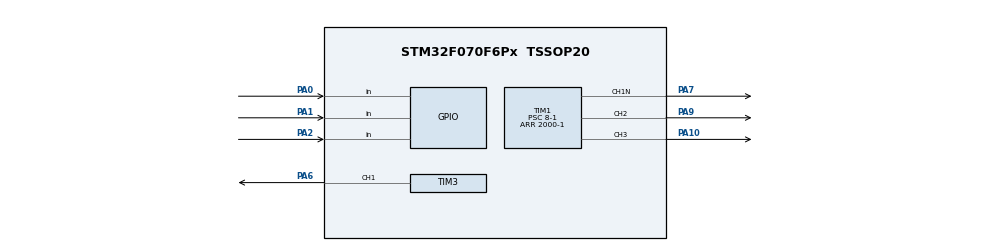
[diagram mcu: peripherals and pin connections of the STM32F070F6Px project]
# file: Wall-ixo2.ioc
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Mcu.Family=STM32F0
Mcu.Name=STM32F070F6Px
Mcu.Package=TSSOP20
PA0.GPIO_PuPd=GPIO_PULLDOWN
PA0.Signal=GPIO_Input
PA1.GPIO_PuPd=GPIO_PULLDOWN
PA1.Signal=GPIO_Input
PA10.Signal=S_TIM1_CH3
PA13.Mode=Serial_Wire
PA13.Signal=SYS_SWDIO
PA14.Mode=Serial_Wire
PA14.Signal=SYS_SWCLK
PA2.GPIO_PuPd=GPIO_PULLDOWN
PA2.Signal=GPIO_Input
PA6.Signal=S_TIM3_CH1
PA7.Mode=PWM Generation1 CH1N
PA7.Signal=TIM1_CH1N
PA9.Signal=S_TIM1_CH2
ProjectManager.HeapSize=0x200
ProjectManager.StackSize=0x400
ProjectManager.TargetToolchain=STM32CubeIDE
SH.S_TIM1_CH2.0=TIM1_CH2,PWM Generation2 CH2
SH.S_TIM1_CH3.0=TIM1_CH3,PWM Generation3 CH3
SH.S_TIM3_CH1.0=TIM3_CH1,PWM Generation1 CH1
TIM1.Channel-PWM\ Generation1\ CH1N=TIM_CHANNEL_1
TIM1.Channel-PWM\ Generation2\ CH2=TIM_CHANNEL_2
TIM1.Channel-PWM\ Generation3\ CH3=TIM_CHANNEL_3
TIM1.Period=2000-1
TIM1.Prescaler=8-1
TIM3.Channel-PWM\ Generation1\ CH1=TIM_CHANNEL_1
TIM3.Period=2000-1
TIM3.Prescaler=8-1
VP_TIM1_VS_ClockSourceINT.Mode=Internal
board=custom

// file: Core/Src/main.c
/* USER CODE BEGIN Header */
/**
  ******************************************************************************
  * @file           : main.c
  * @brief          : Main program body
  ******************************************************************************
  * @attention
  *
  * Copyright (c) 2022 STMicroelectronics.
  * All rights reserved.
  *
  * This software is licensed under terms that can be found in the LICENSE file
  * in the root directory of this software component.
  * If no LICENSE file comes with this software, it is provided AS-IS.
  *
  ******************************************************************************
  */
/* USER CODE END Header */
#include "main.h"

TIM_HandleTypeDef htim1;
TIM_HandleTypeDef htim3;

void SystemClock_Config(void);
static void MX_GPIO_Init(void);
static void MX_TIM1_Init(void);
static void MX_TIM3_Init(void);

int main(void)
{

  /* MCU Configuration--------------------------------------------------------*/

  /* Reset of all peripherals, Initializes the Flash interface and the Systick. */
  HAL_Init();

  /* Configure the system clock */
  SystemClock_Config();

  /* Initialize all configured peripherals */
  MX_GPIO_Init();
  MX_TIM1_Init();
  MX_TIM3_Init();
  /* USER CODE BEGIN 2 */
  	  HAL_TIM_PWM_Start(&htim1, TIM_CHANNEL_1); //PA7
      HAL_TIM_PWM_Start(&htim1, TIM_CHANNEL_2);//PA9
      HAL_TIM_PWM_Start(&htim1, TIM_CHANNEL_3);//PA10
      HAL_TIM_PWM_Start(&htim3, TIM_CHANNEL_1);//PA6
  /* USER CODE END 2 */

  /* Infinite loop */
  while (1)
  {
	  anda();
	  sensorMeio();
	  sensorDireita();
	  sensorEsquerdo();
  }
}
void sensorMeio(){
	if(HAL_GPIO_ReadPin(GPIOA, GPIO_PIN_1)){
			  para();
		      gira90();
	}
}
void sensorEsquerdo(){
	if(HAL_GPIO_ReadPin(GPIOA, GPIO_PIN_0)){
			  para();
		      gira90();
		      para();
		      andaPouco(1000);
		      para();
		      gira90Nega();
		      anda();
	}
}
void sensorDireita(){
	if(HAL_GPIO_ReadPin(GPIOA, GPIO_PIN_2)){
		para();
				      gira90Nega();
				      para();
				      andaPouco(1000);
				      para();
				      gira90();
				      anda();
	}
}
void anda(void){
	//velocidade do motor(NÃO DEFINIDA)
		int vm = 1500;
		//motor 1
		TIM1->CCR3=vm;
		TIM1->CCR2=0;
		//motor2
		TIM1->CCR1 = vm;
		TIM3->CCR1 = 0;
		HAL_Delay(10);
}
void andaPouco(int time){
	//velocidade do motor(NÃO DEFINIDA)
		int vm = 1500;
		//motor 1
		TIM1->CCR3=vm;
		TIM1->CCR2=0;
		//motor2
		TIM1->CCR1 = vm;
		TIM3->CCR1 = 0;
		HAL_Delay(time);
		para();
}
/**
  * @brief  para
  * @retval int
  */
void para(void){
		//motor 1
		TIM1->CCR3=0;
		TIM1->CCR2=0;
		//motor2
		TIM1->CCR1 = 0;
		TIM3->CCR1 = 0;
}

void gira90(void){
	//velocidade de curva do motor(NÃO DEFINIDA)
		int vcurva = 1500;
	//tempo de curva do motor(NÃO DEFINIDO)
		int tvirada = 1200;
	//motor 1 motor esquerda
		TIM1->CCR3 = 0;
		TIM1->CCR2 = vcurva;
	//motor2 motor da direita
		TIM1->CCR1 = vcurva;
		TIM3->CCR1 = 0;
		HAL_Delay(tvirada);
		para();
	//tempo necessario para a curva
	//verificando se passagem está livre
		if(HAL_GPIO_ReadPin(GPIOA, GPIO_PIN_1) == 1){
			gira180();
		}
}
void gira90Nega(void){
	//velocidade de curva do motor(NÃO DEFINIDA)
			int vcurva = 1500;
		//tempo de curva do motor(NÃO DEFINIDO)
			int tvirada = 1200;
		//motor 1 motor esquerda
			TIM1->CCR3 = vcurva;
			TIM1->CCR2 = 0;
		//motor2 motor da direita
			TIM1->CCR1 = 0;
			TIM3->CCR1 = vcurva;
			HAL_Delay(tvirada);
			para();	//verificando se passagem está livre
		if(HAL_GPIO_ReadPin(GPIOA, GPIO_PIN_1) == 1){
			gira180();
		}
}
/**
  * @brief  Função para virar 90 graus,
  * tomando como padrao o lado esquerdo
  * @retval void
  */
void gira180(void){
	//velocidade de curva do motor(NÃO DEFINIDA)
		int vcurva = 1500;
	//tempo de curva do motor(NÃO DEFINIDO)
		int tvirada = 2000;
	//motor 1
		TIM1->CCR3 = vcurva;
		TIM1->CCR2 = 0;
	//motor2
		TIM1->CCR1 = 0;
		TIM3->CCR1 = vcurva;
	//tempo necessario para a curva
		HAL_Delay(2*tvirada);
		//parando motor
		para();
	//verificando se passagem está livre
		if(HAL_GPIO_ReadPin(GPIOA, GPIO_PIN_1) == 1){
			desliga();
		}
}
/**
  * @brief  desligando
  * @retval int
  */
void desliga(){
	//motor 1
		TIM1->CCR3 = 0;
		TIM1->CCR2 = 0;
	//motor2
		TIM1->CCR1 = 0;
		TIM3->CCR1 = 0;
	//desligar vassourinhas e o aspirador;
		//
		//
		//
}
void SystemClock_Config(void)
{
  RCC_OscInitTypeDef RCC_OscInitStruct = {0};
  RCC_ClkInitTypeDef RCC_ClkInitStruct = {0};

  /** Initializes the RCC Oscillators according to the specified parameters
  * in the RCC_OscInitTypeDef structure.
  */
  RCC_OscInitStruct.OscillatorType = RCC_OSCILLATORTYPE_HSI;
  RCC_OscInitStruct.HSIState = RCC_HSI_ON;
  RCC_OscInitStruct.HSICalibrationValue = RCC_HSICALIBRATION_DEFAULT;
  RCC_OscInitStruct.PLL.PLLState = RCC_PLL_NONE;
  if (HAL_RCC_OscConfig(&RCC_OscInitStruct) != HAL_OK)
  {
    Error_Handler();
  }

  /** Initializes the CPU, AHB and APB buses clocks
  */
  RCC_ClkInitStruct.ClockType = RCC_CLOCKTYPE_HCLK|RCC_CLOCKTYPE_SYSCLK
                              |RCC_CLOCKTYPE_PCLK1;
  RCC_ClkInitStruct.SYSCLKSource = RCC_SYSCLKSOURCE_HSI;
  RCC_ClkInitStruct.AHBCLKDivider = RCC_SYSCLK_DIV1;
  RCC_ClkInitStruct.APB1CLKDivider = RCC_HCLK_DIV1;

  if (HAL_RCC_ClockConfig(&RCC_ClkInitStruct, FLASH_LATENCY_0) != HAL_OK)
  {
    Error_Handler();
  }
}

static void MX_TIM1_Init(void)
{

  TIM_ClockConfigTypeDef sClockSourceConfig = {0};
  TIM_MasterConfigTypeDef sMasterConfig = {0};
  TIM_OC_InitTypeDef sConfigOC = {0};
  TIM_BreakDeadTimeConfigTypeDef sBreakDeadTimeConfig = {0};

  htim1.Instance = TIM1;
  htim1.Init.Prescaler = 8-1;
  htim1.Init.CounterMode = TIM_COUNTERMODE_UP;
  htim1.Init.Period = 2000-1;
  htim1.Init.ClockDivision = TIM_CLOCKDIVISION_DIV1;
  htim1.Init.RepetitionCounter = 0;
  htim1.Init.AutoReloadPreload = TIM_AUTORELOAD_PRELOAD_DISABLE;
  if (HAL_TIM_Base_Init(&htim1) != HAL_OK)
  {
    Error_Handler();
  }
  sClockSourceConfig.ClockSource = TIM_CLOCKSOURCE_INTERNAL;
  if (HAL_TIM_ConfigClockSource(&htim1, &sClockSourceConfig) != HAL_OK)
  {
    Error_Handler();
  }
  if (HAL_TIM_PWM_Init(&htim1) != HAL_OK)
  {
    Error_Handler();
  }
  sMasterConfig.MasterOutputTrigger = TIM_TRGO_RESET;
  sMasterConfig.MasterSlaveMode = TIM_MASTERSLAVEMODE_DISABLE;
  if (HAL_TIMEx_MasterConfigSynchronization(&htim1, &sMasterConfig) != HAL_OK)
  {
    Error_Handler();
  }
  sConfigOC.OCMode = TIM_OCMODE_PWM1;
  sConfigOC.Pulse = 0;
  sConfigOC.OCPolarity = TIM_OCPOLARITY_HIGH;
  sConfigOC.OCNPolarity = TIM_OCNPOLARITY_HIGH;
  sConfigOC.OCFastMode = TIM_OCFAST_DISABLE;
  sConfigOC.OCIdleState = TIM_OCIDLESTATE_RESET;
  sConfigOC.OCNIdleState = TIM_OCNIDLESTATE_RESET;
  if (HAL_TIM_PWM_ConfigChannel(&htim1, &sConfigOC, TIM_CHANNEL_1) != HAL_OK)
  {
    Error_Handler();
  }
  if (HAL_TIM_PWM_ConfigChannel(&htim1, &sConfigOC, TIM_CHANNEL_2) != HAL_OK)
  {
    Error_Handler();
  }
  if (HAL_TIM_PWM_ConfigChannel(&htim1, &sConfigOC, TIM_CHANNEL_3) != HAL_OK)
  {
    Error_Handler();
  }
  sBreakDeadTimeConfig.OffStateRunMode = TIM_OSSR_DISABLE;
  sBreakDeadTimeConfig.OffStateIDLEMode = TIM_OSSI_DISABLE;
  sBreakDeadTimeConfig.LockLevel = TIM_LOCKLEVEL_OFF;
  sBreakDeadTimeConfig.DeadTime = 0;
  sBreakDeadTimeConfig.BreakState = TIM_BREAK_DISABLE;
  sBreakDeadTimeConfig.BreakPolarity = TIM_BREAKPOLARITY_HIGH;
  sBreakDeadTimeConfig.AutomaticOutput = TIM_AUTOMATICOUTPUT_DISABLE;
  if (HAL_TIMEx_ConfigBreakDeadTime(&htim1, &sBreakDeadTimeConfig) != HAL_OK)
  {
    Error_Handler();
  }
  HAL_TIM_MspPostInit(&htim1);

}

static void MX_TIM3_Init(void)
{

  TIM_MasterConfigTypeDef sMasterConfig = {0};
  TIM_OC_InitTypeDef sConfigOC = {0};

  htim3.Instance = TIM3;
  htim3.Init.Prescaler = 8-1;
  htim3.Init.CounterMode = TIM_COUNTERMODE_UP;
  htim3.Init.Period = 2000-1;
  htim3.Init.ClockDivision = TIM_CLOCKDIVISION_DIV1;
  htim3.Init.AutoReloadPreload = TIM_AUTORELOAD_PRELOAD_DISABLE;
  if (HAL_TIM_PWM_Init(&htim3) != HAL_OK)
  {
    Error_Handler();
  }
  sMasterConfig.MasterOutputTrigger = TIM_TRGO_RESET;
  sMasterConfig.MasterSlaveMode = TIM_MASTERSLAVEMODE_DISABLE;
  if (HAL_TIMEx_MasterConfigSynchronization(&htim3, &sMasterConfig) != HAL_OK)
  {
    Error_Handler();
  }
  sConfigOC.OCMode = TIM_OCMODE_PWM1;
  sConfigOC.Pulse = 0;
  sConfigOC.OCPolarity = TIM_OCPOLARITY_HIGH;
  sConfigOC.OCFastMode = TIM_OCFAST_DISABLE;
  if (HAL_TIM_PWM_ConfigChannel(&htim3, &sConfigOC, TIM_CHANNEL_1) != HAL_OK)
  {
    Error_Handler();
  }
  HAL_TIM_MspPostInit(&htim3);

}

static void MX_GPIO_Init(void)
{
  GPIO_InitTypeDef GPIO_InitStruct = {0};

  /* GPIO Ports Clock Enable */
  __HAL_RCC_GPIOA_CLK_ENABLE();

  /*Configure GPIO pins : PA0 PA1 PA2 */
  GPIO_InitStruct.Pin = GPIO_PIN_0|GPIO_PIN_1|GPIO_PIN_2;
  GPIO_InitStruct.Mode = GPIO_MODE_INPUT;
  GPIO_InitStruct.Pull = GPIO_PULLDOWN;
  HAL_GPIO_Init(GPIOA, &GPIO_InitStruct);

}

void Error_Handler(void)
{
  __disable_irq();
  while (1)
  {
  }
}
